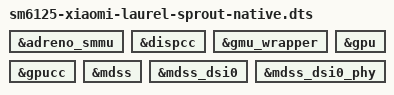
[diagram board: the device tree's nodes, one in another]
// SPDX-License-Identifier: BSD-3-Clause
/* Reuse attributed Mi A3 wiring and the verified boot-critical profile. */
#include "sm6125-xiaomi-laurel-sprout-bringup.dts"

&adreno_smmu {
	status = "okay";
};

&dispcc {
	status = "okay";
};

&gmu_wrapper {
	status = "okay";
};

&gpu {
	status = "okay";
};

&gpucc {
	status = "okay";
};

&mdss {
	/*
	 * The optional core reset request hangs this board during MDSS probe.
	 * Build #15 boots full native recovery when only this request is
	 * omitted. Keep the provider in SM6125; investigate reset sequencing
	 * before restoring the consumer. See NATIVE_GRAPHICS.md.
	 */
	/delete-property/ resets;
	status = "okay";
};

&mdss_dsi0 {
	status = "okay";
};

&mdss_dsi0_phy {
	status = "okay";
};
